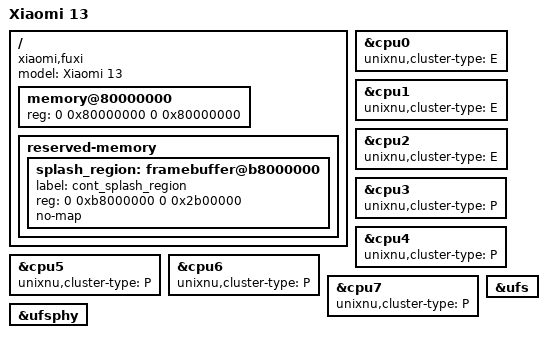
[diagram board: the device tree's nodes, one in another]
// SPDX-License-Identifier: BSD-2-Clause-Patent
// fuxi (Xiaomi 13, SM8550) device tree. Same SoC as sheng; differences noted.
// DDR starts at 0x80000000; 2 GiB window is the kernel-visible one (sheng pattern).
/dts-v1/;
/include/ "sm8550.dtsi"

/ {
    model = "Xiaomi 13";
    compatible = "xiaomi,fuxi", "qcom,sm8550";

    memory@80000000 {
        device_type = "memory";
        reg = <0 0x80000000 0 0x80000000>;
    };

    reserved-memory {
        #address-cells = <2>;
        #size-cells = <2>;
        ranges;
        splash_region: framebuffer@b8000000 {
            label = "cont_splash_region";
            reg = <0 0xb8000000 0 0x2b00000>;
            no-map;
        };
    };
};

// cpu0-2 = A510 (E cluster), cpu3-7 = P cluster.
&cpu0 { unixnu,cluster-type = "E"; };
&cpu1 { unixnu,cluster-type = "E"; };
&cpu2 { unixnu,cluster-type = "E"; };
&cpu3 { unixnu,cluster-type = "P"; };
&cpu4 { unixnu,cluster-type = "P"; };
&cpu5 { unixnu,cluster-type = "P"; };
&cpu6 { unixnu,cluster-type = "P"; };
&cpu7 { unixnu,cluster-type = "P"; };
&ufs { status = "okay"; };
&ufsphy { status = "okay"; };
